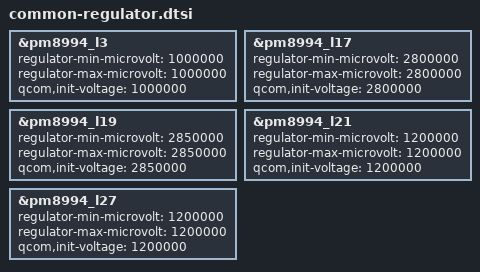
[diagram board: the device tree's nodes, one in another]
&pm8994_l3 {
	regulator-min-microvolt = <1000000>;
	regulator-max-microvolt = <1000000>;
	qcom,init-voltage = <1000000>;
};

&pm8994_l17 {
	regulator-min-microvolt = <2800000>;
	regulator-max-microvolt = <2800000>;
	qcom,init-voltage = <2800000>;
};

&pm8994_l19 {
	regulator-min-microvolt = <2850000>;
	regulator-max-microvolt = <2850000>;
	qcom,init-voltage = <2850000>;
};

&pm8994_l21 {
	regulator-min-microvolt = <1200000>;
	regulator-max-microvolt = <1200000>;
	qcom,init-voltage = <1200000>;
};

&pm8994_l27 {
	regulator-min-microvolt = <1200000>;
	regulator-max-microvolt = <1200000>;
	qcom,init-voltage = <1200000>;
};
